AUTOSAR XML (schema 00046)
package /ComponentTypes
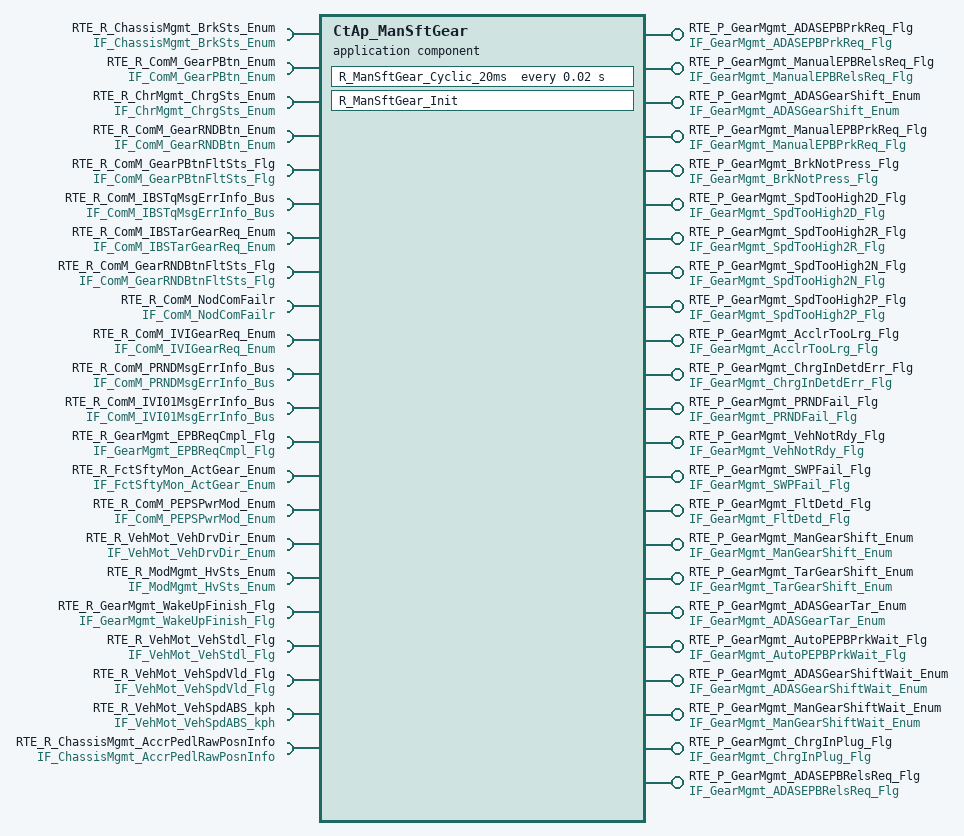
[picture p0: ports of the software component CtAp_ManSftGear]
  application sw component type CtAp_ManSftGear
    20 x require port:
      RTE_R_ChassisMgmt_BrkSts_Enum: nonqueued-receiver-com-spec{data-element=tec_ChassisMgmt_BrkSts_Enum, filter=data-filter-type=ALWAYS, init-value=0}, required-interface=IF_ChassisMgmt_BrkSts_Enum
      RTE_R_ComM_GearPBtn_Enum: nonqueued-receiver-com-spec{data-element=tec_ComM_GearPBtn_Enum, filter=data-filter-type=ALWAYS, init-value=0}, required-interface=IF_ComM_GearPBtn_Enum
      RTE_R_ChrMgmt_ChrgSts_Enum: nonqueued-receiver-com-spec{data-element=tec_ChrMgmt_ChrgSts_Enum, filter=data-filter-type=ALWAYS, init-value=0}, required-interface=IF_ChrMgmt_ChrgSts_Enum
      RTE_R_ComM_GearRNDBtn_Enum: nonqueued-receiver-com-spec{data-element=tec_ComM_GearRNDBtn_Enum, filter=data-filter-type=ALWAYS, init-value=0}, required-interface=IF_ComM_GearRNDBtn_Enum
      RTE_R_ComM_GearPBtnFltSts_Flg: nonqueued-receiver-com-spec{data-element=tec_ComM_GearPBtnFltSts_Flg, filter=data-filter-type=ALWAYS, init-value=0}, required-interface=IF_ComM_GearPBtnFltSts_Flg
      RTE_R_ComM_IBSTqMsgErrInfo_Bus: required-interface=IF_ComM_IBSTqMsgErrInfo_Bus
        required-com-specs:
          data-element=tec_ComM_IBSTqCRCDTCInfo_Bus, filter=data-filter-type=ALWAYS, init-value=fields=[ComM_MonStatIBSTqCRCDTCErrorInfo:0, ComM_MonResIBSTqCRCDTCErrorInfo:0, ComM_ErrStatIBSTqCRCDTCErrorInfo:0, ComM_ErrResIBSTqCRCDTCErrorInfo:0]
          data-element=tec_ComM_IBSTqTimeoutDTCInfo_Bus, filter=data-filter-type=ALWAYS, init-value=fields=[ComM_MonStatIBSTqTimeoutDTCErrorInfo:0, ComM_MonResIBSTqTimeoutDTCErrorInfo:0, ComM_ErrStatIBSTqTimeoutDTCErrorInfo:0, ComM_ErrResIBSTqTimeoutDTCErrorInfo:0]
          data-element=tec_ComM_IBSTqCRCInfo_Bus, filter=data-filter-type=ALWAYS, init-value=fields=[ComM_MonStatIBSTqCRCErrorInfo:0, ComM_MonResIBSTqCRCErrorInfo:0, ComM_ErrStatIBSTqCRCErrorInfo:0, ComM_ErrResIBSTqCRCErrorInfo:0]
          data-element=tec_ComM_IBSTqE2ETimeoutInfo_Bus, filter=data-filter-type=ALWAYS, init-value=fields=[ComM_MonStatIBSTqE2ETimeoutInfo:0, ComM_MonResIBSTqE2ETimeoutInfo:0, ComM_ErrStatIBSTqE2ETimeoutInfo:0, ComM_ErrResIBSTqE2ETimeoutInfo:0]
      RTE_R_ComM_IBSTarGearReq_Enum: nonqueued-receiver-com-spec{data-element=tec_ComM_IBSTarGearReq_Enum, filter=data-filter-type=ALWAYS, init-value=0}, required-interface=IF_ComM_IBSTarGearReq_Enum
      RTE_R_ComM_GearRNDBtnFltSts_Flg: nonqueued-receiver-com-spec{data-element=tec_ComM_GearRNDBtnFltSts_Flg, filter=data-filter-type=ALWAYS, init-value=0}, required-interface=IF_ComM_GearRNDBtnFltSts_Flg
      RTE_R_ComM_NodComFailr: required-interface=IF_ComM_NodComFailr
        required-com-specs:
          data-element=tec_ComM_ACUNodComFailr_Flg, filter=data-filter-type=ALWAYS, init-value=0
          data-element=tec_ComM_SGWNodComFailr_Flg, filter=data-filter-type=ALWAYS, init-value=0
          data-element=tec_ComM_CGWNodComFailr_Flg, filter=data-filter-type=ALWAYS, init-value=0
          data-element=tec_ComM_TCUNodComFailr_Flg, filter=data-filter-type=ALWAYS, init-value=0
          data-element=tec_ComM_BCMNodComFailr_Flg, filter=data-filter-type=ALWAYS, init-value=0
          data-element=tec_ComM_PRNDNodComFailr_Flg, filter=data-filter-type=ALWAYS, init-value=0
          data-element=tec_ComM_IVINodComFailr_Flg, filter=data-filter-type=ALWAYS, init-value=0
          data-element=tec_ComM_DCDCNodComFailr_Flg, filter=data-filter-type=ALWAYS, init-value=0
          data-element=tec_ComM_OBCNodComFailr_Flg, filter=data-filter-type=ALWAYS, init-value=0
          data-element=tec_ComM_CHIBSNodComFailr_Flg, filter=data-filter-type=ALWAYS, init-value=0
          data-element=tec_ComM_MCUNodComFailr_Flg, filter=data-filter-type=ALWAYS, init-value=0
          data-element=tec_ComM_EVCOMNodComFailr_Flg, filter=data-filter-type=ALWAYS, init-value=0
          data-element=tec_ComM_EPTIBSNodComFailr_Flg, filter=data-filter-type=ALWAYS, init-value=0
          data-element=tec_ComM_DCMNodComFailr_Flg, filter=data-filter-type=ALWAYS, init-value=0
          data-element=tec_ComM_BMSNodComFailr_Flg, filter=data-filter-type=ALWAYS, init-value=0
          data-element=tec_ComM_APTCNodComFailr_Flg, filter=data-filter-type=ALWAYS, init-value=0
          data-element=tec_ComM_ADCUNodComFailr_Flg, filter=data-filter-type=ALWAYS, init-value=0
          data-element=tec_ComM_DCMRRNodComFailr_Flg, filter=data-filter-type=ALWAYS, init-value=0
          data-element=tec_ComM_DCMRLNodComFailr_Flg, filter=data-filter-type=ALWAYS, init-value=0
          data-element=tec_ComM_DCMFRNodComFailr_Flg, filter=data-filter-type=ALWAYS, init-value=0
          data-element=tec_ComM_DCMFLNodComFailr_Flg, filter=data-filter-type=ALWAYS, init-value=0
          data-element=tec_ComM_SGWCHNodComFailr_Flg, init-value=0
      RTE_R_ComM_IVIGearReq_Enum: nonqueued-receiver-com-spec{data-element=tec_ComM_IVIGearReq_Enum, filter=data-filter-type=ALWAYS, init-value=0}, required-interface=IF_ComM_IVIGearReq_Enum
      RTE_R_ComM_PRNDMsgErrInfo_Bus: required-interface=IF_ComM_PRNDMsgErrInfo_Bus
        required-com-specs:
          data-element=tec_ComM_PRNDTimeoutInfo_Bus, filter=data-filter-type=ALWAYS, init-value=fields=[ComM_MonStatPRNDTimeoutInfo:0, ComM_MonResPRNDTimeoutInfo:0, ComM_ErrStatPRNDTimeoutInfo:0, ComM_ErrResPRNDTimeoutInfo:0]
          data-element=tec_ComM_PRNDCRCDTCInfo_Bus, filter=data-filter-type=ALWAYS, init-value=fields=[ComM_MonStatPRNDCRCDTCErrorInfo:0, ComM_MonResPRNDCRCDTCErrorInfo:0, ComM_ErrStatPRNDCRCDTCErrorInfo:0, ComM_ErrResPRNDCRCDTCErrorInfo:0]
          data-element=tec_ComM_PRNDCRCInfo_Bus, filter=data-filter-type=ALWAYS, init-value=fields=[ComM_MonStatPRNDCRCErrorInfo:0, ComM_MonResPRNDCRCErrorInfo:0, ComM_ErrStatPRNDCRCErrorInfo:0, ComM_ErrResPRNDCRCErrorInfo:0]
          data-element=tec_ComM_PRNDTimeoutDTCInfo_Bus, filter=data-filter-type=ALWAYS, init-value=fields=[ComM_MonStatPRNDTimeoutDTCErrorInfo:0, ComM_MonResPRNDTimeoutDTCErrorInfo:0, ComM_ErrStatPRNDTimeoutDTCErrorInfo:0, ComM_ErrResPRNDTimeoutDTCErrorInfo:0]
          data-element=tec_ComM_PRNDE2ETimeoutInfo_Bus, filter=data-filter-type=ALWAYS, init-value=fields=[ComM_MonStatPRNDE2ETimeoutInfo:0, ComM_MonResPRNDE2ETimeoutInfo:0, ComM_ErrStatPRNDE2ETimeoutInfo:0, ComM_ErrResPRNDE2ETimeoutInfo:0]
      RTE_R_ComM_IVI01MsgErrInfo_Bus: required-interface=IF_ComM_IVI01MsgErrInfo_Bus
        required-com-specs:
          data-element=tec_ComM_IVI01CRCInfo_Bus, filter=data-filter-type=ALWAYS, init-value=fields=[ComM_MonStatIVI01CRCErrorInfo:0, ComM_MonResIVI01CRCErrorInfo:0, ComM_ErrStatIVI01CRCErrorInfo:0, ComM_ErrResIVI01CRCErrorInfo:0]
          data-element=tec_ComM_IVI01E2ETimeoutInfo_Bus, filter=data-filter-type=ALWAYS, init-value=fields=[ComM_MonStatIVI01E2ETimeoutInfo:0, ComM_MonResIVI01E2ETimeoutInfo:0, ComM_ErrStatIVI01E2ETimeoutInfo:0, ComM_ErrResIVI01E2ETimeoutInfo:0]
      RTE_R_GearMgmt_EPBReqCmpl_Flg: nonqueued-receiver-com-spec{data-element=tec_GearMgmt_EPBReqCmpl_Flg, filter=data-filter-type=ALWAYS, init-value=0}, required-interface=IF_GearMgmt_EPBReqCmpl_Flg
      RTE_R_FctSftyMon_ActGear_Enum: nonqueued-receiver-com-spec{data-element=tec_FctSftyMon_ActGear_Enum, filter=data-filter-type=ALWAYS, init-value=0}, required-interface=IF_FctSftyMon_ActGear_Enum
      RTE_R_ComM_PEPSPwrMod_Enum: nonqueued-receiver-com-spec{data-element=tec_ComM_PEPSPwrMod_Enum, filter=data-filter-type=ALWAYS, init-value=0}, required-interface=IF_ComM_PEPSPwrMod_Enum
      RTE_R_VehMot_VehDrvDir_Enum: nonqueued-receiver-com-spec{data-element=tec_VehMot_VehDrvDir_Enum, filter=data-filter-type=ALWAYS, init-value=0}, required-interface=IF_VehMot_VehDrvDir_Enum
      RTE_R_ModMgmt_HvSts_Enum: nonqueued-receiver-com-spec{data-element=tec_ModMgmt_HvSts_Enum, filter=data-filter-type=ALWAYS, init-value=0}, required-interface=IF_ModMgmt_HvSts_Enum
      RTE_R_GearMgmt_WakeUpFinish_Flg: nonqueued-receiver-com-spec{data-element=tec_GearMgmt_WakeUpFinish_Flg, filter=data-filter-type=ALWAYS, init-value=0}, required-interface=IF_GearMgmt_WakeUpFinish_Flg
      RTE_R_VehMot_VehStdl_Flg: nonqueued-receiver-com-spec{data-element=tec_VehMot_VehStdl_Flg, filter=data-filter-type=ALWAYS, init-value=0}, required-interface=IF_VehMot_VehStdl_Flg
      RTE_R_VehMot_VehSpdVld_Flg: nonqueued-receiver-com-spec{data-element=tec_VehMot_VehSpdVld_Flg, filter=data-filter-type=ALWAYS, init-value=0}, required-interface=IF_VehMot_VehSpdVld_Flg
    23 x provide port:
      RTE_P_GearMgmt_ADASEPBPrkReq_Flg: nonqueued-sender-com-spec{data-element=tec_GearMgmt_ADASEPBPrkReq_Flg, init-value=0}, provided-interface=IF_GearMgmt_ADASEPBPrkReq_Flg
      RTE_P_GearMgmt_ManualEPBRelsReq_Flg: nonqueued-sender-com-spec{data-element=tec_GearMgmt_ManualEPBRelsReq_Flg, init-value=0}, provided-interface=IF_GearMgmt_ManualEPBRelsReq_Flg
      RTE_P_GearMgmt_ADASGearShift_Enum: nonqueued-sender-com-spec{data-element=tec_GearMgmt_ADASGearShift_Enum, init-value=0}, provided-interface=IF_GearMgmt_ADASGearShift_Enum
      RTE_P_GearMgmt_ManualEPBPrkReq_Flg: nonqueued-sender-com-spec{data-element=tec_GearMgmt_ManualEPBPrkReq_Flg, init-value=0}, provided-interface=IF_GearMgmt_ManualEPBPrkReq_Flg
      RTE_P_GearMgmt_BrkNotPress_Flg: nonqueued-sender-com-spec{data-element=tec_GearMgmt_BrkNotPress_Flg, init-value=0}, provided-interface=IF_GearMgmt_BrkNotPress_Flg
      RTE_P_GearMgmt_SpdTooHigh2D_Flg: nonqueued-sender-com-spec{data-element=tec_GearMgmt_SpdTooHigh2D_Flg, init-value=0}, provided-interface=IF_GearMgmt_SpdTooHigh2D_Flg
      RTE_P_GearMgmt_SpdTooHigh2R_Flg: nonqueued-sender-com-spec{data-element=tec_GearMgmt_SpdTooHigh2R_Flg, init-value=0}, provided-interface=IF_GearMgmt_SpdTooHigh2R_Flg
      RTE_P_GearMgmt_SpdTooHigh2N_Flg: nonqueued-sender-com-spec{data-element=tec_GearMgmt_SpdTooHigh2N_Flg, init-value=0}, provided-interface=IF_GearMgmt_SpdTooHigh2N_Flg
      RTE_P_GearMgmt_SpdTooHigh2P_Flg: nonqueued-sender-com-spec{data-element=tec_GearMgmt_SpdTooHigh2P_Flg, init-value=0}, provided-interface=IF_GearMgmt_SpdTooHigh2P_Flg
      RTE_P_GearMgmt_AcclrTooLrg_Flg: nonqueued-sender-com-spec{data-element=tec_GearMgmt_AcclrTooLrg_Flg, init-value=0}, provided-interface=IF_GearMgmt_AcclrTooLrg_Flg
      RTE_P_GearMgmt_ChrgInDetdErr_Flg: nonqueued-sender-com-spec{data-element=tec_GearMgmt_ChrgInDetdErr_Flg, init-value=0}, provided-interface=IF_GearMgmt_ChrgInDetdErr_Flg
      RTE_P_GearMgmt_PRNDFail_Flg: nonqueued-sender-com-spec{data-element=tec_GearMgmt_PRNDFail_Flg, init-value=0}, provided-interface=IF_GearMgmt_PRNDFail_Flg
      RTE_P_GearMgmt_VehNotRdy_Flg: nonqueued-sender-com-spec{data-element=tec_GearMgmt_VehNotRdy_Flg, init-value=0}, provided-interface=IF_GearMgmt_VehNotRdy_Flg
      RTE_P_GearMgmt_SWPFail_Flg: nonqueued-sender-com-spec{data-element=tec_GearMgmt_SWPFail_Flg, init-value=0}, provided-interface=IF_GearMgmt_SWPFail_Flg
      RTE_P_GearMgmt_FltDetd_Flg: nonqueued-sender-com-spec{data-element=tec_GearMgmt_FltDetd_Flg, init-value=0}, provided-interface=IF_GearMgmt_FltDetd_Flg
      RTE_P_GearMgmt_ManGearShift_Enum: nonqueued-sender-com-spec{data-element=tec_GearMgmt_ManGearShift_Enum, init-value=0}, provided-interface=IF_GearMgmt_ManGearShift_Enum
      RTE_P_GearMgmt_TarGearShift_Enum: nonqueued-sender-com-spec{data-element=tec_GearMgmt_ManualGearTar_Enum, init-value=0}, provided-interface=IF_GearMgmt_TarGearShift_Enum
      RTE_P_GearMgmt_ADASGearTar_Enum: nonqueued-sender-com-spec{data-element=tec_GearMgmt_ADASGearTar_Enum, init-value=0}, provided-interface=IF_GearMgmt_ADASGearTar_Enum
      RTE_P_GearMgmt_AutoPEPBPrkWait_Flg: nonqueued-sender-com-spec{data-element=tec_GearMgmt_AutoPEPBPrkWait_Flg, init-value=0}, provided-interface=IF_GearMgmt_AutoPEPBPrkWait_Flg
      RTE_P_GearMgmt_ADASGearShiftWait_Enum: nonqueued-sender-com-spec{data-element=tec_GearMgmt_ADASGearShiftWait_Enum, init-value=0}, provided-interface=IF_GearMgmt_ADASGearShiftWait_Enum
      RTE_P_GearMgmt_ManGearShiftWait_Enum: nonqueued-sender-com-spec{data-element=tec_GearMgmt_ManGearShiftWait_Enum, init-value=0}, provided-interface=IF_GearMgmt_ManGearShiftWait_Enum
      RTE_P_GearMgmt_ChrgInPlug_Flg: nonqueued-sender-com-spec{data-element=tec_GearMgmt_ChrgInPlug_Flg, init-value=0}, provided-interface=IF_GearMgmt_ChrgInPlug_Flg
      RTE_P_GearMgmt_ADASEPBRelsReq_Flg: nonqueued-sender-com-spec{data-element=tec_GearMgmt_ADASEPBRelsReq_Flg, init-value=0}, provided-interface=IF_GearMgmt_ADASEPBRelsReq_Flg
    require port RTE_R_VehMot_VehSpdABS_kph: nonqueued-receiver-com-spec{data-element=tec_VehMot_VehSpdABS_kph, filter=data-filter-type=ALWAYS, init-value=0}, required-interface=IF_VehMot_VehSpdABS_kph
    require port RTE_R_ChassisMgmt_AccrPedlRawPosnInfo: nonqueued-receiver-com-spec{data-element=tec_ChassisMgmt_AccrPedlRawPosnInfo, filter=data-filter-type=ALWAYS, init-value=0}, required-interface=IF_ChassisMgmt_AccrPedlRawPosnInfo
    behavior CtAp_ManSftGear_InternalBehavior
      timing event TMT_R_ManSftGear_Cyclic_20ms: start-on-event=R_ManSftGear_Cyclic_20ms, period=0.02
      init event CtAp_ManSftGear_InitEvent: start-on-event=R_ManSftGear_Init
      runnable R_ManSftGear_Cyclic_20ms
        data-receive-point-by-arguments:
          28 x access:
            REC_RTE_R_ChassisMgmt_BrkSts_Enum_tec_ChassisMgmt_BrkSts_Enum: accessed-variable=RTE_R_ChassisMgmt_BrkSts_Enum.tec_ChassisMgmt_BrkSts_Enum
            REC_RTE_R_ChrMgmt_ChrgSts_Enum_tec_ChrMgmt_ChrgSts_Enum: accessed-variable=RTE_R_ChrMgmt_ChrgSts_Enum.tec_ChrMgmt_ChrgSts_Enum
            REC_RTE_R_ComM_GearPBtnFltSts_Flg_tec_ComM_GearPBtnFltSts_Flg: accessed-variable=RTE_R_ComM_GearPBtnFltSts_Flg.tec_ComM_GearPBtnFltSts_Flg
            REC_RTE_R_ComM_GearPBtn_Enum_tec_ComM_GearPBtn_Enum: accessed-variable=RTE_R_ComM_GearPBtn_Enum.tec_ComM_GearPBtn_Enum
            REC_RTE_R_ComM_GearRNDBtnFltSts_Flg_tec_ComM_GearRNDBtnFltSts_Flg: accessed-variable=RTE_R_ComM_GearRNDBtnFltSts_Flg.tec_ComM_GearRNDBtnFltSts_Flg
            REC_RTE_R_ComM_GearRNDBtn_Enum_tec_ComM_GearRNDBtn_Enum: accessed-variable=RTE_R_ComM_GearRNDBtn_Enum.tec_ComM_GearRNDBtn_Enum
            REC_RTE_R_ComM_IBSTarGearReq_Enum_tec_ComM_IBSTarGearReq_Enum: accessed-variable=RTE_R_ComM_IBSTarGearReq_Enum.tec_ComM_IBSTarGearReq_Enum
            REC_RTE_R_ComM_IBSTqMsgErrInfo_Bus_tec_ComM_IBSTqCRCInfo_Bus: accessed-variable=RTE_R_ComM_IBSTqMsgErrInfo_Bus.tec_ComM_IBSTqCRCInfo_Bus
            REC_RTE_R_ComM_IBSTqMsgErrInfo_Bus_tec_ComM_IBSTqE2ETimeoutInfo_Bus: accessed-variable=RTE_R_ComM_IBSTqMsgErrInfo_Bus.tec_ComM_IBSTqE2ETimeoutInfo_Bus
            REC_RTE_R_ComM_IVI01MsgErrInfo_Bus_tec_ComM_IVI01CRCInfo_Bus: accessed-variable=RTE_R_ComM_IVI01MsgErrInfo_Bus.tec_ComM_IVI01CRCInfo_Bus
            REC_RTE_R_ComM_IVI01MsgErrInfo_Bus_tec_ComM_IVI01E2ETimeoutInfo_Bus: accessed-variable=RTE_R_ComM_IVI01MsgErrInfo_Bus.tec_ComM_IVI01E2ETimeoutInfo_Bus
            REC_RTE_R_ComM_IVIGearReq_Enum_tec_ComM_IVIGearReq_Enum: accessed-variable=RTE_R_ComM_IVIGearReq_Enum.tec_ComM_IVIGearReq_Enum
            REC_RTE_R_ComM_NodComFailr_tec_ComM_BCMNodComFailr_Flg: accessed-variable=RTE_R_ComM_NodComFailr.tec_ComM_BCMNodComFailr_Flg
            REC_RTE_R_ComM_NodComFailr_tec_ComM_CHIBSNodComFailr_Flg: accessed-variable=RTE_R_ComM_NodComFailr.tec_ComM_CHIBSNodComFailr_Flg
            REC_RTE_R_ComM_NodComFailr_tec_ComM_IVINodComFailr_Flg: accessed-variable=RTE_R_ComM_NodComFailr.tec_ComM_IVINodComFailr_Flg
            REC_RTE_R_ComM_NodComFailr_tec_ComM_PRNDNodComFailr_Flg: accessed-variable=RTE_R_ComM_NodComFailr.tec_ComM_PRNDNodComFailr_Flg
            REC_RTE_R_ComM_PEPSPwrMod_Enum_tec_ComM_PEPSPwrMod_Enum: accessed-variable=RTE_R_ComM_PEPSPwrMod_Enum.tec_ComM_PEPSPwrMod_Enum
            REC_RTE_R_ComM_PRNDMsgErrInfo_Bus_tec_ComM_PRNDCRCInfo_Bus: accessed-variable=RTE_R_ComM_PRNDMsgErrInfo_Bus.tec_ComM_PRNDCRCInfo_Bus
            REC_RTE_R_ComM_PRNDMsgErrInfo_Bus_tec_ComM_PRNDE2ETimeoutInfo_Bus: accessed-variable=RTE_R_ComM_PRNDMsgErrInfo_Bus.tec_ComM_PRNDE2ETimeoutInfo_Bus
            REC_RTE_R_FctSftyMon_ActGear_Enum_tec_FctSftyMon_ActGear_Enum: accessed-variable=RTE_R_FctSftyMon_ActGear_Enum.tec_FctSftyMon_ActGear_Enum
            REC_RTE_R_GearMgmt_EPBReqCmpl_Flg_tec_GearMgmt_EPBReqCmpl_Flg: accessed-variable=RTE_R_GearMgmt_EPBReqCmpl_Flg.tec_GearMgmt_EPBReqCmpl_Flg
            REC_RTE_R_GearMgmt_WakeUpFinish_Flg_tec_GearMgmt_WakeUpFinish_Flg: accessed-variable=RTE_R_GearMgmt_WakeUpFinish_Flg.tec_GearMgmt_WakeUpFinish_Flg
            REC_RTE_R_ModMgmt_HvSts_Enum_tec_ModMgmt_HvSts_Enum: accessed-variable=RTE_R_ModMgmt_HvSts_Enum.tec_ModMgmt_HvSts_Enum
            REC_RTE_R_VehMot_VehDrvDir_Enum_tec_VehMot_VehDrvDir_Enum: accessed-variable=RTE_R_VehMot_VehDrvDir_Enum.tec_VehMot_VehDrvDir_Enum
            REC_RTE_R_VehMot_VehSpdVld_Flg_tec_VehMot_VehSpdVld_Flg: accessed-variable=RTE_R_VehMot_VehSpdVld_Flg.tec_VehMot_VehSpdVld_Flg
            REC_RTE_R_VehMot_VehStdl_Flg_tec_VehMot_VehStdl_Flg: accessed-variable=RTE_R_VehMot_VehStdl_Flg.tec_VehMot_VehStdl_Flg
            REC_RTE_R_VehMot_VehSpdABS_kph_tec_VehMot_VehSpdABS_kph: accessed-variable=RTE_R_VehMot_VehSpdABS_kph.tec_VehMot_VehSpdABS_kph
            REC_RTE_R_ChassisMgmt_AccrPedlRawPosnInfo_tec_ChassisMgmt_AccrPedlRawPosnInfo: accessed-variable=RTE_R_ChassisMgmt_AccrPedlRawPosnInfo.tec_ChassisMgmt_AccrPedlRawPosnInfo
        data-send-points:
          23 x access:
            SEND_RTE_P_GearMgmt_VehNotRdy_Flg_tec_GearMgmt_VehNotRdy_Flg: accessed-variable=RTE_P_GearMgmt_VehNotRdy_Flg.tec_GearMgmt_VehNotRdy_Flg
            SEND_RTE_P_GearMgmt_TarGearShift_Enum_tec_GearMgmt_ManualGearTar_Enum: accessed-variable=RTE_P_GearMgmt_TarGearShift_Enum.tec_GearMgmt_ManualGearTar_Enum
            SEND_RTE_P_GearMgmt_SWPFail_Flg_tec_GearMgmt_SWPFail_Flg: accessed-variable=RTE_P_GearMgmt_SWPFail_Flg.tec_GearMgmt_SWPFail_Flg
            SEND_RTE_P_GearMgmt_SpdTooHigh2R_Flg_tec_GearMgmt_SpdTooHigh2R_Flg: accessed-variable=RTE_P_GearMgmt_SpdTooHigh2R_Flg.tec_GearMgmt_SpdTooHigh2R_Flg
            SEND_RTE_P_GearMgmt_SpdTooHigh2P_Flg_tec_GearMgmt_SpdTooHigh2P_Flg: accessed-variable=RTE_P_GearMgmt_SpdTooHigh2P_Flg.tec_GearMgmt_SpdTooHigh2P_Flg
            SEND_RTE_P_GearMgmt_SpdTooHigh2N_Flg_tec_GearMgmt_SpdTooHigh2N_Flg: accessed-variable=RTE_P_GearMgmt_SpdTooHigh2N_Flg.tec_GearMgmt_SpdTooHigh2N_Flg
            SEND_RTE_P_GearMgmt_SpdTooHigh2D_Flg_tec_GearMgmt_SpdTooHigh2D_Flg: accessed-variable=RTE_P_GearMgmt_SpdTooHigh2D_Flg.tec_GearMgmt_SpdTooHigh2D_Flg
            SEND_RTE_P_GearMgmt_PRNDFail_Flg_tec_GearMgmt_PRNDFail_Flg: accessed-variable=RTE_P_GearMgmt_PRNDFail_Flg.tec_GearMgmt_PRNDFail_Flg
            SEND_RTE_P_GearMgmt_ManualEPBRelsReq_Flg_tec_GearMgmt_ManualEPBRelsReq_Flg: accessed-variable=RTE_P_GearMgmt_ManualEPBRelsReq_Flg.tec_GearMgmt_ManualEPBRelsReq_Flg
            SEND_RTE_P_GearMgmt_ManualEPBPrkReq_Flg_tec_GearMgmt_ManualEPBPrkReq_Flg: accessed-variable=RTE_P_GearMgmt_ManualEPBPrkReq_Flg.tec_GearMgmt_ManualEPBPrkReq_Flg
            SEND_RTE_P_GearMgmt_ManGearShiftWait_Enum_tec_GearMgmt_ManGearShiftWait_Enum: accessed-variable=RTE_P_GearMgmt_ManGearShiftWait_Enum.tec_GearMgmt_ManGearShiftWait_Enum
            SEND_RTE_P_GearMgmt_ManGearShift_Enum_tec_GearMgmt_ManGearShift_Enum: accessed-variable=RTE_P_GearMgmt_ManGearShift_Enum.tec_GearMgmt_ManGearShift_Enum
            SEND_RTE_P_GearMgmt_FltDetd_Flg_tec_GearMgmt_FltDetd_Flg: accessed-variable=RTE_P_GearMgmt_FltDetd_Flg.tec_GearMgmt_FltDetd_Flg
            SEND_RTE_P_GearMgmt_ChrgInPlug_Flg_tec_GearMgmt_ChrgInPlug_Flg: accessed-variable=RTE_P_GearMgmt_ChrgInPlug_Flg.tec_GearMgmt_ChrgInPlug_Flg
            SEND_RTE_P_GearMgmt_ChrgInDetd_Flg_tec_GearMgmt_ChrgInDetdErr_Flg: accessed-variable=RTE_P_GearMgmt_ChrgInDetdErr_Flg.tec_GearMgmt_ChrgInDetdErr_Flg
            SEND_RTE_P_GearMgmt_BrkNotPress_Flg_tec_GearMgmt_BrkNotPress_Flg: accessed-variable=RTE_P_GearMgmt_BrkNotPress_Flg.tec_GearMgmt_BrkNotPress_Flg
            SEND_RTE_P_GearMgmt_AutoPEPBPrkWait_Flg_tec_GearMgmt_AutoPEPBPrkWait_Flg: accessed-variable=RTE_P_GearMgmt_AutoPEPBPrkWait_Flg.tec_GearMgmt_AutoPEPBPrkWait_Flg
            SEND_RTE_P_GearMgmt_ADASGearTar_Enum_tec_GearMgmt_ADASGearTar_Enum: accessed-variable=RTE_P_GearMgmt_ADASGearTar_Enum.tec_GearMgmt_ADASGearTar_Enum
            SEND_RTE_P_GearMgmt_ADASGearShiftWait_Enum_tec_GearMgmt_ADASGearShiftWait_Enum: accessed-variable=RTE_P_GearMgmt_ADASGearShiftWait_Enum.tec_GearMgmt_ADASGearShiftWait_Enum
            SEND_RTE_P_GearMgmt_ADASGearShift_Enum_tec_GearMgmt_ADASGearShift_Enum: accessed-variable=RTE_P_GearMgmt_ADASGearShift_Enum.tec_GearMgmt_ADASGearShift_Enum
            SEND_RTE_P_GearMgmt_ADASEPBPrkReq_Flg_tec_GearMgmt_ADASEPBPrkReq_Flg: accessed-variable=RTE_P_GearMgmt_ADASEPBPrkReq_Flg.tec_GearMgmt_ADASEPBPrkReq_Flg
            SEND_RTE_P_GearMgmt_AcclrTooLrg_Flg_tec_GearMgmt_AcclrTooLrg_Flg: accessed-variable=RTE_P_GearMgmt_AcclrTooLrg_Flg.tec_GearMgmt_AcclrTooLrg_Flg
            SEND_RTE_P_GearMgmt_ADASEPBRelsReq_Flg_tec_GearMgmt_ADASEPBRelsReq_Flg: accessed-variable=RTE_P_GearMgmt_ADASEPBRelsReq_Flg.tec_GearMgmt_ADASEPBRelsReq_Flg
      runnable R_ManSftGear_Init
  swc implementation CtAp_ManSftGear_Implementation: behavior=CtAp_ManSftGear_InternalBehavior
